AUTOSAR XML (schema 4-2-2)
package /ComponentTypes
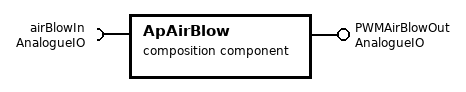
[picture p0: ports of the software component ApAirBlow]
  composition sw component type ApAirBlow
    require port airBlowIn: required-interface=AnalogueIO
    provide port PWMAirBlowOut: provided-interface=AnalogueIO
    component AirBlow: type=AirBlow
    component AirBlowOut: type=AirBlowOut
    delegate AirBlowOut.pwmBlowerSpeedOut <-> outer port airBlowIn
    delegate AirBlow.PWMBlowerMotorSpeed <-> outer port PWMAirBlowOut
